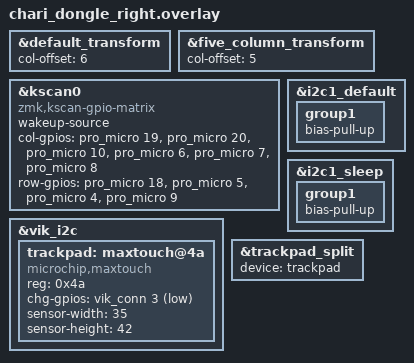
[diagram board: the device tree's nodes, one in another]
#include "chari.dtsi"

&default_transform {
	col-offset = <6>;
};

&five_column_transform {
	col-offset = <5>;
};

&kscan0 {
	compatible = "zmk,kscan-gpio-matrix";
	wakeup-source;

	col-gpios
		= <&pro_micro 19 (GPIO_ACTIVE_HIGH | GPIO_PULL_DOWN)>
		, <&pro_micro 20 (GPIO_ACTIVE_HIGH | GPIO_PULL_DOWN)>
		, <&pro_micro 10 (GPIO_ACTIVE_HIGH | GPIO_PULL_DOWN)>
		, <&pro_micro 6 (GPIO_ACTIVE_HIGH | GPIO_PULL_DOWN)>
		, <&pro_micro 7 (GPIO_ACTIVE_HIGH | GPIO_PULL_DOWN)>
		, <&pro_micro 8 (GPIO_ACTIVE_HIGH | GPIO_PULL_DOWN)>
		;

	row-gpios
		= <&pro_micro 18 GPIO_ACTIVE_HIGH>
		, <&pro_micro 5 GPIO_ACTIVE_HIGH>
		, <&pro_micro 4 GPIO_ACTIVE_HIGH>
		, <&pro_micro 9 GPIO_ACTIVE_HIGH>
		;
};

/* Procyon trackpad via VIK I2C */
&i2c1_default {
	group1 {
		bias-pull-up;
	};
};

&i2c1_sleep {
	group1 {
		bias-pull-up;
	};
};

&vik_i2c {
	status = "okay";

	trackpad: maxtouch@4a {
		compatible = "microchip,maxtouch";
		reg = <0x4a>;
		chg-gpios = <&vik_conn 3 (GPIO_ACTIVE_LOW | GPIO_PULL_UP)>;
		sensor-width = <35>;
		sensor-height = <42>;
	};
};

/* Dongle mode: right is peripheral, forward trackpad to central via input-split */
&trackpad_split {
	device = <&trackpad>;
};
